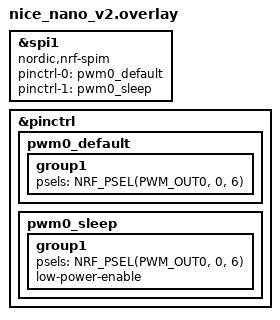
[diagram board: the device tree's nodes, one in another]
#include <dt-bindings/led/led.h>

&spi1 {
	compatible = "nordic,nrf-spim";

	status = "okay";

	pinctrl-0 = <&pwm0_default>;
	pinctrl-1 = <&pwm0_sleep>;
	pinctrl-names = "default", "sleep";
};

&pinctrl {
	pwm0_default: pwm0_default {
		group1 {
			psels = <NRF_PSEL(PWM_OUT0, 0, 6)>;
		};
	};
	pwm0_sleep: pwm0_sleep {
		group1 {
			psels = <NRF_PSEL(PWM_OUT0, 0, 6)>;
			low-power-enable;
		};
	};
};

